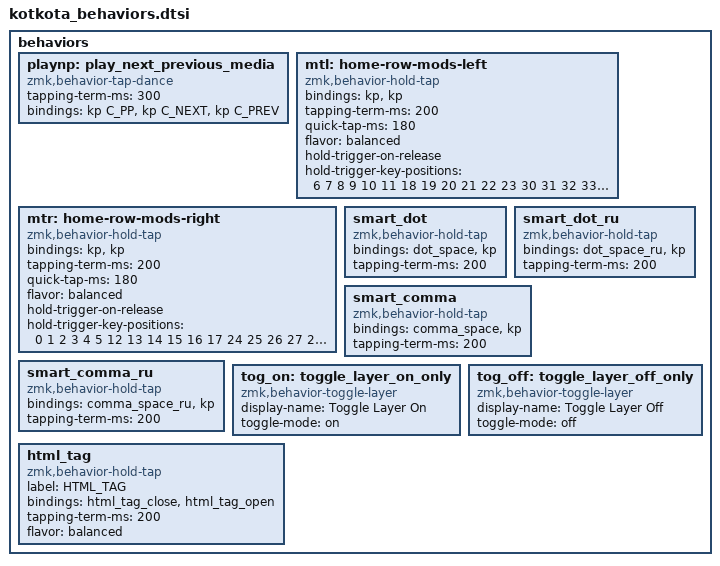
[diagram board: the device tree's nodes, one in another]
behaviors {
  /omit-if-no-ref/

  playnp: play_next_previous_media {
    compatible = "zmk,behavior-tap-dance";
    #binding-cells = <0>;
    tapping-term-ms = <300>;
    bindings = <&kp C_PP>, <&kp C_NEXT>, <&kp C_PREV>;
  };

  mtl: home-row-mods-left {
    compatible = "zmk,behavior-hold-tap";
    bindings = <&kp>, <&kp>;

    #binding-cells = <2>;
    tapping-term-ms = <200>;
    quick-tap-ms = <180>;
    flavor = "balanced";
    hold-trigger-on-release;
    hold-trigger-key-positions = <6 7 8 9 10 11 18 19 20 21 22 23 30 31 32 33 34 35 40 41 39 38 37 36 12 24>;
  };

  mtr: home-row-mods-right {
    compatible = "zmk,behavior-hold-tap";
    bindings = <&kp>, <&kp>;

    #binding-cells = <2>;
    tapping-term-ms = <200>;
    quick-tap-ms = <180>;
    flavor = "balanced";
    hold-trigger-on-release;
    hold-trigger-key-positions = <0 1 2 3 4 5 12 13 14 15 16 17 24 25 26 27 28 29 36 37 38 39 40 41>;
  };

  smart_dot: smart_dot {
    compatible = "zmk,behavior-hold-tap";
    bindings = <&dot_space>, <&kp>;

    #binding-cells = <2>;
    tapping-term-ms = <200>;
  };

  smart_dot_ru: smart_dot_ru {
    compatible = "zmk,behavior-hold-tap";
    bindings = <&dot_space_ru>, <&kp>;

    #binding-cells = <2>;
    tapping-term-ms = <200>;
  };

  smart_comma: smart_comma {
    compatible = "zmk,behavior-hold-tap";
    bindings = <&comma_space>, <&kp>;

    #binding-cells = <2>;
    tapping-term-ms = <200>;
  };

  smart_comma_ru: smart_comma_ru {
    compatible = "zmk,behavior-hold-tap";
    bindings = <&comma_space_ru>, <&kp>;

    #binding-cells = <2>;
    tapping-term-ms = <200>;
  };

  tog_on: toggle_layer_on_only {
    compatible = "zmk,behavior-toggle-layer";
    #binding-cells = <1>;
    display-name = "Toggle Layer On";
    toggle-mode = "on";
  };

  tog_off: toggle_layer_off_only {
    compatible = "zmk,behavior-toggle-layer";
    #binding-cells = <1>;
    display-name = "Toggle Layer Off";
    toggle-mode = "off";
  };

  html_tag: html_tag {
    compatible = "zmk,behavior-hold-tap";
    label = "HTML_TAG";
    bindings = <&html_tag_close>, <&html_tag_open>;

    #binding-cells = <2>;
    tapping-term-ms = <200>;
    flavor = "balanced";
  };
};
